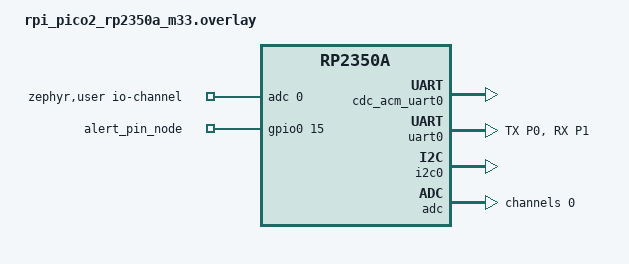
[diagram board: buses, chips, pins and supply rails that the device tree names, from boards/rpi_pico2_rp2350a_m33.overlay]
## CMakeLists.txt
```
cmake_minimum_required(VERSION 3.20.0)

# Select our board 
set(BOARD rpi_pico2/rp2350a/m33)


# Find/Select cmake package 'Zephyr' 
find_package(Zephyr)

# This is only used by IntelliSense inside VS Code 
set(CMAKE_EXPORT_COMPILE_COMMANDS ON)

# For using west flash with picoprobe
# set(OPENOCD "openocd")
# set(OPENOCD_DEFAULT_PATH "/usr/local/share/openocd/scripts")

# Define project name
project(sensor-node)

# Add include directory 
target_include_directories(app PRIVATE src/inc src/inc/humidity-sensor src/inc/light-sensor src/inc/moisture-sensor src/inc/temp-sensor)

FILE(GLOB SRC_FILES
    "src/*.c"
    "src/inc/*.c"
    "src/inc/humidity-sensor/*.c"
    "src/inc/light-sensor/*.c"
    "src/inc/moisture-sensor/*.c"
    "src/inc/temp-sensor/*.c"
)

target_sources(app PRIVATE ${SRC_FILES})
```

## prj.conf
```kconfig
CONFIG_SERIAL=y
CONFIG_CONSOLE=y
CONFIG_UART_CONSOLE=y
CONFIG_STDOUT_CONSOLE=y
CONFIG_UART_LINE_CTRL=y

CONFIG_USB_DEVICE_STACK_NEXT=y
CONFIG_CDC_ACM_SERIAL_INITIALIZE_AT_BOOT=y
CONFIG_CDC_ACM_SERIAL_PRODUCT_STRING="WCNES G2 Sensor Node"

CONFIG_I2C=y
CONFIG_I2C_TARGET=y

CONFIG_ADC=y
CONFIG_SENSOR=y
```

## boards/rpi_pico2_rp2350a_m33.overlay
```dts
#include <zephyr/dt-bindings/adc/adc.h>

/ {
    chosen {
		zephyr,console = &cdc_acm_uart0;
	};
    
    zephyr,user {
		io-channels = <&adc 0>;
	};
    
    aliases {
        alert-gpio = &alert_pin_node;
    };

    gpio_outputs {
        compatible = "gpio-leds";       /* gives DTC the binding it needs */
        alert_pin_node: alert_pin_node {
            gpios = <&gpio0 15 0>;      /* 0 = GPIO_ACTIVE_HIGH */
        };
    };
};

&zephyr_udc0 {
	cdc_acm_uart0: cdc_acm_uart0 {
		compatible = "zephyr,cdc-acm-uart";
	};
};

&pinctrl {
    /* Define non-conflicting pins for UART0 (TX on GPIO 0, RX on GPIO 1) */
    uart0_default: uart0_default {
        group1 {
            pinmux = <UART0_TX_P0>;
        };
        group2 {
            pinmux = <UART0_RX_P1>;
            input-enable;
        };
    };

    /* Define non-conflicting pins for I2C0 (SDA on GPIO 4, SCL on GPIO 5) */
    i2c0_default: i2c0_default {
        group1 {
            pinmux = <I2C0_SDA_P4>, <I2C0_SCL_P5>;
            input-enable;
            input-schmitt-enable; /* Recommended for I2C signal integrity */
			bias-pull-up;
        };
    };

    i2c1_default: i2c1_default {
        group1 {
            pinmux = <I2C1_SDA_P6>, <I2C1_SCL_P7>;
            input-enable;
            input-schmitt-enable; /* Recommended for I2C signal integrity */
			bias-pull-up;
        };
    };
};


&uart0 {
    status = "okay";
    pinctrl-0 = <&uart0_default>;
    pinctrl-names = "default";
};

&i2c0 {
    status = "okay";
    pinctrl-0 = <&i2c0_default>;
    pinctrl-names = "default";
};



&adc {
	#address-cells = <1>;
	#size-cells = <0>;

	channel@0 {
		reg = <0>;
		zephyr,gain = "ADC_GAIN_1";
		zephyr,reference = "ADC_REF_INTERNAL";
		zephyr,acquisition-time = <ADC_ACQ_TIME_DEFAULT>;
		zephyr,resolution = <12>;
	};
};
```

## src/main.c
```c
#include "handler_interface.h"
#include "humidity_sensor.h"
#include "light_sensor.h"
#include "moisture_sensor.h"
#include "sensor_registers.h"
#include "temp_sensor.h"

#include <zephyr/drivers/gpio.h>
#include <zephyr/drivers/i2c.h>
#include <zephyr/kernel.h>
#include <zephyr/sys/printk.h>

static const struct gpio_dt_spec alert_pin = GPIO_DT_SPEC_GET(DT_ALIAS(alert_gpio), gpios);

#define SLEEP_PERIOD_MS 1000
// The the time in ms one unit in SENSOR_LIGHT_TIME_THRESHOLD is, e.g. 10 * min == 600000 ms
#define TIMEOUT_UNIT_MS 600000
static const struct device *bus = DEVICE_DT_GET(DT_NODELABEL(i2c1));
static const struct device *sensor_i2c_bus = DEVICE_DT_GET(DT_NODELABEL(i2c0));
static const struct adc_dt_spec adc_chan = ADC_DT_SPEC_GET(DT_PATH(zephyr_user));

static int32_t temperature = 42069;
static float humidity = 42069;
static uint16_t soil_moisture = 42069;
static float lux = 42069;

static volatile uint8_t low_light_timeout = 0;
static volatile int64_t deadline = 0;
static volatile uint8_t light_level_threshold = 0;
static volatile bool light_interupt_enabled = false;

int handle_read(uint8_t reg, uint8_t *to_send, size_t *bytes_to_send) {
    switch (reg) {
    case SENSOR_TEMPRATURE: {
        memcpy(to_send, &temperature, sizeof(temperature));
        *bytes_to_send = sizeof(temperature);
        break;
    }
    case SENSOR_HUMIDITY: {
        memcpy(to_send, &humidity, sizeof(humidity));
        *bytes_to_send = sizeof(humidity);
        break;
    }
    case SENSOR_SOIL: {
        memcpy(to_send, &soil_moisture, sizeof(soil_moisture));
        *bytes_to_send = sizeof(soil_moisture);
        break;
    }
    case SENSOR_LIGHT: {
        memcpy(to_send, &lux, sizeof(lux));
        *bytes_to_send = sizeof(lux);
        break;
    }

    default:
        printk("unknown\n");
        break;
    }
    return 0;
}

int handle_write(uint8_t reg, uint8_t val) {
    printk("[write] To 0x%02x with 0x%02x ", reg, val);
    switch (reg) {
    case SENSOR_LIGHT_LEVEL_THRESHOLD:
        light_level_threshold = val;
        printk("Light Level Threshold\n");
        break;

    case SENSOR_LIGHT_TIME_THRESHOLD:
        low_light_timeout = val;
        printk("Light Time Threshold\n");
        break;
    case SENSOR_LIGHT_INTERUPT_ENABLE:
        light_interupt_enabled = true;
        deadline = k_uptime_get() + low_light_timeout * TIMEOUT_UNIT_MS;
        printk("Light Interupt Enabled\n");
        break;
    default:
        printk("unknown\n");
        break;
    }
    return 0;
}

int main(void) {

    handler_config_t cfg = (handler_config_t){
        .handle_read = handle_read,
        .handle_write = handle_write,
        .address = 0x60,
    };

    int ret;
    if ((ret = register_target_with_handlers(bus, &cfg)) != 0) {
        printk("register: %d\n", ret);
        while (true) {
            printk("ERR: %d\n", ret);
        }
    }

    ret = gpio_pin_configure_dt(&alert_pin, GPIO_OUTPUT_INACTIVE);
    if (ret < 0) {
        return ret;
    }

    k_msleep(3000);
    printk("init_temp_sensor: %d\n", init_temp_sensor(&adc_chan));
    printk("init_humidity_sensor: %d\n", init_humidity_sensor(sensor_i2c_bus));
    printk("init_light_sensor: %d\n", init_light_sensor(sensor_i2c_bus));
    printk("init_moisture_sensor: %d\n", init_moisture_sensor(sensor_i2c_bus));

    while (1) {
        k_msleep(SLEEP_PERIOD_MS);
        int r1 = read_temp_sensor(&temperature);
        int r2 = read_humidity_sensor(&humidity);
        int r3 = read_light_sensor(&lux);
        int r4 = read_moisture_sensor(&soil_moisture);

        if (r1 != 0) {
            printk("ERR read_temp_sensor: %d\n", r1);
        }
        if (r2 != 0) {
            printk("ERR read_humidity_sensor: %d\n", r2);
        }
        if (r3 != 0) {
            printk("ERR read_light_sensor: %d\n", r3);
        }
        if (r4 != 0) {
            printk("ERR read_moisture_sensor: %d\n", r4);
        }

        if (light_interupt_enabled) {
            int64_t now = k_uptime_get();
            printk("TIMER %lld\n", deadline - now);
            if (lux <= (float)light_level_threshold) {
                if (now >= deadline) {
                    gpio_pin_set_dt(&alert_pin, 1);
                    k_msleep(1);
                    gpio_pin_set_dt(&alert_pin, 0);
                    deadline = now + low_light_timeout * TIMEOUT_UNIT_MS;
                }
            } else {
                deadline = now + low_light_timeout * TIMEOUT_UNIT_MS;
            }
        }
    }
}
```

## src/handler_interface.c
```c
#include "handler_interface.h"
#include <stdalign.h>
#include <zephyr/drivers/i2c.h>
#include <zephyr/sys/printk.h>
// Implementation of
// https://mermaid.live/edit#pako:eNp1kktPwzAMgP9K5CPqRpd2feSAxOOKhMoBCYqmsLhdxZqUPMZg2n8nXbfBBORkO99nS4k3MFcCgUEpjeUWbxpea96OVrSUxJ-ns2cyGl3cW9V1KIbaPunr5EE3Fgt8c2gsCnaSD_Qp0TuXQugC5yuyxwfuWO2Rw4g9Qc7JgkuxxJnGevb-j1Sg6ZQUV67yXoFceM2gdR15cVWFmlhF7HoQf7Cn8_roT-RX9zut5miMt0pZSgig1o0AZrXDAFrULe9T2PTdSrALbLEE5kPB9WvpH3zrnY7LR6Xag6aVqxfAKr40PnOd-P6SI4JSoL5WTlpgaRbvegDbwBoYTabjhOZRMonzKMr7yw9gcTTO85AmeTwJwyxJtwF87maG4zSdZNM8itOMhjSjAaBorNK3w07sVmP7BcyqreI
enum COMM_STATE { COMM_STOPPED,
                  COMM_WRITE_REQUESTED,
                  COMM_ADDR_RECIVED,
                  COMM_BUF_SEND };

typedef struct comm_state_machine {
    alignas(float) char send_buf[MAX_BUF_SIZE];
    size_t msg_len; // must be <= MAX_BUF_SIZE
    int cursor;     // must be < MAX_BUF_SIZE
    uint8_t addr;
    enum COMM_STATE state;

} comm_state_machine_t;

static comm_state_machine_t comm = (comm_state_machine_t){
    .state = COMM_STOPPED,
    .addr = 0,
};

static handler_config_t *registered_config = NULL;

static int write_requested_cb(struct i2c_target_config *config) {
    comm.state = COMM_WRITE_REQUESTED;
    return 0;
}

static int write_received_cb(struct i2c_target_config *config, uint8_t val) {

    switch (comm.state) {
    case COMM_WRITE_REQUESTED:
        comm.addr = val;
        comm.state = COMM_ADDR_RECIVED;
        break;

    case COMM_ADDR_RECIVED:
        registered_config->handle_write(comm.addr, val);
        break;
    default:
        printk("Unexpected write received\n");
        break;
    }

    return 0;
}

static int read_requested_cb(struct i2c_target_config *config, uint8_t *out) {

    if (comm.state == COMM_ADDR_RECIVED) {
        comm.msg_len = 0;
        registered_config->handle_read(comm.addr, comm.send_buf, &comm.msg_len);
        *out = comm.send_buf[0];
        comm.state = COMM_BUF_SEND;
        // printk("read request: %d  : %02x %02x %02x %02x\n", comm.msg_len, comm.send_buf[0], comm.send_buf[1], comm.send_buf[2], comm.send_buf[3]);
        comm.cursor = 1;
    } else {
        printk("Unexpected read: 0x%02x\n", *out);
    }

    return 0;
}

static int read_processed_cb(struct i2c_target_config *config, uint8_t *val) {
    // TOOO:figure out what all this means
    if (comm.state == COMM_BUF_SEND && comm.cursor < comm.msg_len) {
        *val = comm.send_buf[comm.cursor];
        comm.cursor++;
    } else {
        *val = 0xff;
    }

    printk("read processed: 0x%02x\n", *val);
    return 0;
}

static int stop_cb(struct i2c_target_config *config) {
    // printk("sample target stop callback\n");
    comm.state = COMM_STOPPED;
    return 0;
}

static void error_cb(struct i2c_target_config *config, enum i2c_error_reason error_code) {
    printk("target error %d\n", error_code);
}

static struct i2c_target_callbacks callbacks = {
    .write_requested = write_requested_cb,
    .write_received = write_received_cb,
    .read_requested = read_requested_cb,
    .read_processed = read_processed_cb,
    .stop = stop_cb,
    .error = error_cb};

static struct i2c_target_config i2c_cfg = {
    .address = 0x60,
    .callbacks = &callbacks,
    .flags = 0,
};

int register_target_with_handlers(const struct device *dev, handler_config_t *cfg) {
    if (cfg == NULL || registered_config != NULL) {
        return -EINVAL;
    }

    i2c_cfg.address = cfg->address;

    int ret = i2c_target_register(dev, &i2c_cfg);
    if (ret != 0) {
        return ret;
    }

    registered_config = cfg;
    return 0;
}
```

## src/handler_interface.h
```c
#include <zephyr/kernel.h>

#define MAX_BUF_SIZE sizeof(float)
typedef int (*handle_read_t)(uint8_t reg, uint8_t *to_send, size_t *bytes_to_send);
typedef int (*handle_reg_write_t)(uint8_t reg, uint8_t out);

typedef struct handler_config {
    uint16_t address;
    handle_read_t handle_read;
    handle_reg_write_t handle_write;
} handler_config_t;

int register_target_with_handlers(const struct device *dev, handler_config_t *cfg);
```

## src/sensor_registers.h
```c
#define SENSOR_INDEX(reg)    (reg & 0b11110000)
#define SENSOR_REGISTER(reg) (reg & 0b1111)

// | Reg  | R/W | typ       | Använding
// | ---  | --- | --------- | ------------------ |
// | 0x20 | R   | u16       | Läs temperatur     |
// | 0x30 | R   | float     | Läs luftfuktighet  |
// | 0x40 | R   | u16       | Läs jordfuktighet  |
// | 0x50 | R   | float     | Läs ljusstyrka lux |
// | 0x51 |   W | byte      | Sätt tröskelvärde  |
// | 0x52 |   W | byte      | Sätt längdtröskel  |

#define SENSOR_TEMPRATURE            0x20
#define SENSOR_HUMIDITY              0x30
#define SENSOR_SOIL                  0x40
#define SENSOR_LIGHT                 0x50
#define SENSOR_LIGHT_LEVEL_THRESHOLD 0x51
#define SENSOR_LIGHT_TIME_THRESHOLD  0x52
#define SENSOR_LIGHT_INTERUPT_ENABLE 0x53
```
